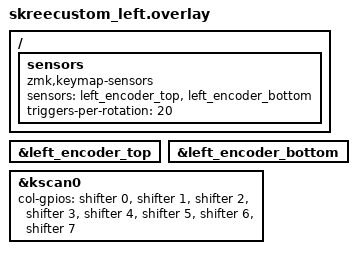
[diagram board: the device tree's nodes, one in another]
#include "skreecustom.dtsi"

&left_encoder_top {
    status = "okay";
};

&left_encoder_bottom {
    status = "okay";
};

/ {
    sensors {
        compatible = "zmk,keymap-sensors";
        sensors = <&left_encoder_top &left_encoder_bottom>;
        triggers-per-rotation = <20>;
    };
};

&kscan0 {
    col-gpios
        = <&shifter 0 GPIO_ACTIVE_HIGH>
        , <&shifter 1 GPIO_ACTIVE_HIGH>
        , <&shifter 2 GPIO_ACTIVE_HIGH>
        , <&shifter 3 GPIO_ACTIVE_HIGH>
        , <&shifter 4 GPIO_ACTIVE_HIGH>
        , <&shifter 5 GPIO_ACTIVE_HIGH>
        , <&shifter 6 GPIO_ACTIVE_HIGH>
        , <&shifter 7 GPIO_ACTIVE_HIGH>
        ;
};
